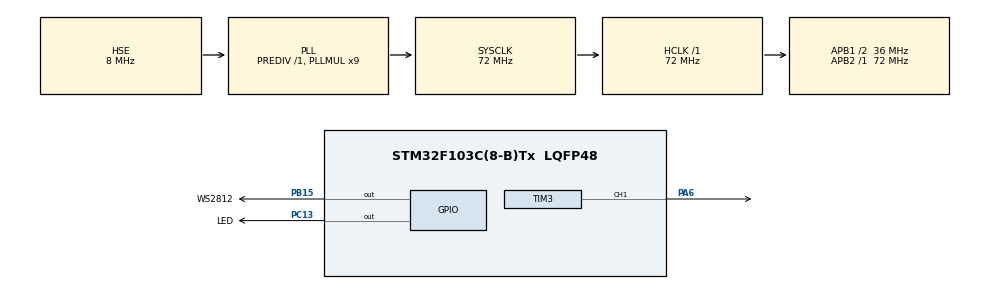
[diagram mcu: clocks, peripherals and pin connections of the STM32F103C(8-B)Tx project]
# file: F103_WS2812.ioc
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Dma.Request0=TIM3_CH1/TRIG
Dma.TIM3_CH1/TRIG.0.Direction=DMA_MEMORY_TO_PERIPH
Dma.TIM3_CH1/TRIG.0.Instance=DMA1_Channel6
Dma.TIM3_CH1/TRIG.0.MemDataAlignment=DMA_MDATAALIGN_BYTE
Dma.TIM3_CH1/TRIG.0.MemInc=DMA_MINC_ENABLE
Dma.TIM3_CH1/TRIG.0.Mode=DMA_NORMAL
Dma.TIM3_CH1/TRIG.0.PeriphDataAlignment=DMA_PDATAALIGN_BYTE
Dma.TIM3_CH1/TRIG.0.PeriphInc=DMA_PINC_DISABLE
Dma.TIM3_CH1/TRIG.0.Priority=DMA_PRIORITY_LOW
Mcu.Family=STM32F1
Mcu.Name=STM32F103C(8-B)Tx
Mcu.Package=LQFP48
NVIC.DMA1_Channel6_IRQn=true\:0\:0\:false\:false\:true\:false\:true
NVIC.PriorityGroup=NVIC_PRIORITYGROUP_4
PA13.Mode=Serial_Wire
PA13.Signal=SYS_JTMS-SWDIO
PA14.Mode=Serial_Wire
PA14.Signal=SYS_JTCK-SWCLK
PA6.Signal=S_TIM3_CH1
PB15.GPIO_Label=WS2812
PB15.GPIO_PuPd=GPIO_PULLUP
PB15.GPIO_Speed=GPIO_SPEED_FREQ_HIGH
PB15.Signal=GPIO_Output
PC13-TAMPER-RTC.GPIO_Label=LED
PC13-TAMPER-RTC.Signal=GPIO_Output
PC14-OSC32_IN.Mode=LSE-External-Oscillator
PC14-OSC32_IN.Signal=RCC_OSC32_IN
PC15-OSC32_OUT.Mode=LSE-External-Oscillator
PC15-OSC32_OUT.Signal=RCC_OSC32_OUT
PD0-OSC_IN.Mode=HSE-External-Oscillator
PD0-OSC_IN.Signal=RCC_OSC_IN
PD1-OSC_OUT.Mode=HSE-External-Oscillator
PD1-OSC_OUT.Signal=RCC_OSC_OUT
ProjectManager.HeapSize=0x200
ProjectManager.StackSize=0x400
ProjectManager.TargetToolchain=MDK-ARM V5
RCC.AHBFreq_Value=72000000
RCC.APB1CLKDivider=RCC_HCLK_DIV2
RCC.APB1Freq_Value=36000000
RCC.APB1TimFreq_Value=72000000
RCC.APB2Freq_Value=72000000
RCC.APB2TimFreq_Value=72000000
RCC.HCLKFreq_Value=72000000
RCC.PLLMUL=RCC_PLL_MUL9
RCC.PLLSourceVirtual=RCC_PLLSOURCE_HSE
RCC.SYSCLKFreq_VALUE=72000000
RCC.SYSCLKSource=RCC_SYSCLKSOURCE_PLLCLK
RCC.USBFreq_Value=72000000
SH.S_TIM3_CH1.0=TIM3_CH1,PWM Generation1 CH1
TIM3.Channel-PWM\ Generation1\ CH1=TIM_CHANNEL_1
TIM3.Period=89
board=custom

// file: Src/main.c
/* USER CODE BEGIN Header */
/**
  ******************************************************************************
  * @file           : main.c
  * @brief          : Main program body
  ******************************************************************************
  * @attention
  *
  * <h2><center>&copy; Copyright (c) 2022 STMicroelectronics.
  * All rights reserved.</center></h2>
  *
  * This software component is licensed by ST under BSD 3-Clause license,
  * the "License"; You may not use this file except in compliance with the
  * License. You may obtain a copy of the License at:
  *                        opensource.org/licenses/BSD-3-Clause
  *
  ******************************************************************************
  */
/* USER CODE END Header */

#include "main.h"
#include "dma.h"
#include "tim.h"
#include "gpio.h"

/* USER CODE BEGIN Includes */
#define PI (3.1415926f)
#include "ws2812.h"

#include "cmath"
/* USER CODE END Includes */

void SystemClock_Config(void);

/* USER CODE BEGIN 0 */
uint8_t makeTriangle(uint16_t index)
{
	uint8_t rtn = (uint8_t)(index&0xff);
	if(index & 0x100)
	{
		rtn = 255-rtn;
	}

	return rtn;
}

uint8_t makeSmoothChange(uint16_t index)
{
	uint8_t rtn = (uint8_t)(index&0xff);
	if(index & 0x100)
	{
		rtn = 255-rtn;
	}

	double vtan = tan((	((double)((int)(rtn))-110) /300.f)*PI);
	vtan = (vtan+2.3)*10;
	vtan = vtan>255?255:vtan;
	vtan = vtan<0?0:vtan;
	rtn = (uint8_t)((int)vtan);
	return rtn;
}
/* USER CODE END 0 */

int main(void)
{
  /* USER CODE BEGIN 1 */
	uint8_t R=0xff,G=0xf,B=0xf;
	uint16_t count = 0;
	uint8_t color_stage = 0;
  /* USER CODE END 1 */

  /* MCU Configuration--------------------------------------------------------*/

  /* Reset of all peripherals, Initializes the Flash interface and the Systick. */
  HAL_Init();

  /* Configure the system clock */
  SystemClock_Config();

  /* Initialize all configured peripherals */
  MX_GPIO_Init();
  MX_DMA_Init();
  MX_TIM3_Init();
  /* USER CODE BEGIN 2 */
	WS28xx_TypeStructInit();

  /* USER CODE END 2 */

  /* Infinite loop */
  /* USER CODE BEGIN WHILE */
  while (1)
  {
		count++;
		if(count%512==0) color_stage++;
		R=0;G=0;B=0;
		switch(color_stage){
			case 0:
				R = makeSmoothChange(count);
				break;
			case 1:
				G = makeSmoothChange(count);
				break;
			case 2:
				B = makeSmoothChange(count);
				break;
			case 3:
				WS28xx.SetALLColor_RGB (0,0,0);WS28xx.show();HAL_Delay(200);
				WS28xx.SetALLColor_RGB (255,128,0);WS28xx.show ();HAL_Delay(80);
				WS28xx.SetALLColor_RGB (0,0,0);WS28xx.show();HAL_Delay(200);
				WS28xx.SetALLColor_RGB (255,128,0);WS28xx.show ();HAL_Delay(80);
				WS28xx.SetALLColor_RGB (0,0,0);WS28xx.show();HAL_Delay(500);

				WS28xx.SetALLColor_RGB (0,0,0);WS28xx.show();HAL_Delay(200);
				WS28xx.SetALLColor_RGB (0,255,128);WS28xx.show ();HAL_Delay(80);
				WS28xx.SetALLColor_RGB (0,0,0);WS28xx.show();HAL_Delay(200);
				WS28xx.SetALLColor_RGB (0,255,128);WS28xx.show ();HAL_Delay(80);
				WS28xx.SetALLColor_RGB (0,0,0);WS28xx.show();HAL_Delay(500);

				WS28xx.SetALLColor_RGB (0,0,0);WS28xx.show();HAL_Delay(200);
				WS28xx.SetALLColor_RGB (128,0,255);WS28xx.show ();HAL_Delay(80);
				WS28xx.SetALLColor_RGB (0,0,0);WS28xx.show();HAL_Delay(200);
				WS28xx.SetALLColor_RGB (128,0,255);WS28xx.show ();HAL_Delay(80);
				WS28xx.SetALLColor_RGB (0,0,0);WS28xx.show();HAL_Delay(500);

				color_stage = 0;

				break;

			default:
				color_stage = 0;
		}
		WS28xx.SetALLColor_RGB (R,G,B);	//R,G,B
		WS28xx.show ();

		HAL_GPIO_TogglePin(LED_GPIO_Port,LED_Pin);
		HAL_Delay(1);
    /* USER CODE END WHILE */

  }
}

void SystemClock_Config(void)
{
  RCC_OscInitTypeDef RCC_OscInitStruct = {0};
  RCC_ClkInitTypeDef RCC_ClkInitStruct = {0};

  /** Initializes the CPU, AHB and APB busses clocks
  */
  RCC_OscInitStruct.OscillatorType = RCC_OSCILLATORTYPE_HSE;
  RCC_OscInitStruct.HSEState = RCC_HSE_ON;
  RCC_OscInitStruct.HSEPredivValue = RCC_HSE_PREDIV_DIV1;
  RCC_OscInitStruct.HSIState = RCC_HSI_ON;
  RCC_OscInitStruct.PLL.PLLState = RCC_PLL_ON;
  RCC_OscInitStruct.PLL.PLLSource = RCC_PLLSOURCE_HSE;
  RCC_OscInitStruct.PLL.PLLMUL = RCC_PLL_MUL9;
  if (HAL_RCC_OscConfig(&RCC_OscInitStruct) != HAL_OK)
  {
    Error_Handler();
  }
  /** Initializes the CPU, AHB and APB busses clocks
  */
  RCC_ClkInitStruct.ClockType = RCC_CLOCKTYPE_HCLK|RCC_CLOCKTYPE_SYSCLK
                              |RCC_CLOCKTYPE_PCLK1|RCC_CLOCKTYPE_PCLK2;
  RCC_ClkInitStruct.SYSCLKSource = RCC_SYSCLKSOURCE_PLLCLK;
  RCC_ClkInitStruct.AHBCLKDivider = RCC_SYSCLK_DIV1;
  RCC_ClkInitStruct.APB1CLKDivider = RCC_HCLK_DIV2;
  RCC_ClkInitStruct.APB2CLKDivider = RCC_HCLK_DIV1;

  if (HAL_RCC_ClockConfig(&RCC_ClkInitStruct, FLASH_LATENCY_2) != HAL_OK)
  {
    Error_Handler();
  }
}

void Error_Handler(void)
{
}

/************************ (C) COPYRIGHT STMicroelectronics *****END OF FILE****/
